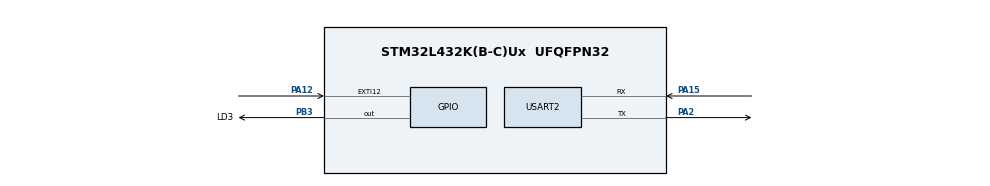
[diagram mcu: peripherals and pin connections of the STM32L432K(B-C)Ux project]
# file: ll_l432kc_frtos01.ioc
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Mcu.Family=STM32L4
Mcu.Name=STM32L432K(B-C)Ux
Mcu.Package=UFQFPN32
NVIC.EXTI15_10_IRQn=true\:5\:0\:true\:false\:true\:true\:true\:true
NVIC.PriorityGroup=NVIC_PRIORITYGROUP_4
NVIC.USART2_IRQn=true\:5\:0\:true\:false\:true\:true\:true\:true
PA12.GPIO_PuPd=GPIO_PULLUP
PA12.Signal=GPXTI12
PA13\ (JTMS-SWDIO).GPIO_Label=SWDIO
PA13\ (JTMS-SWDIO).Mode=Serial_Wire
PA13\ (JTMS-SWDIO).Signal=SYS_JTMS-SWDIO
PA14\ (JTCK-SWCLK).GPIO_Label=SWCLK
PA14\ (JTCK-SWCLK).Mode=Serial_Wire
PA14\ (JTCK-SWCLK).Signal=SYS_JTCK-SWCLK
PA15\ (JTDI).Mode=Asynchronous
PA15\ (JTDI).Signal=USART2_RX
PA2.Mode=Asynchronous
PA2.Signal=USART2_TX
PB3\ (JTDO-TRACESWO).GPIO_Label=LD3
PB3\ (JTDO-TRACESWO).Signal=GPIO_Output
PC14-OSC32_IN\ (PC14).Mode=LSE-External-Oscillator
PC14-OSC32_IN\ (PC14).Signal=RCC_OSC32_IN
PC15-OSC32_OUT\ (PC15).Mode=LSE-External-Oscillator
PC15-OSC32_OUT\ (PC15).Signal=RCC_OSC32_OUT
ProjectManager.HeapSize=0x200
ProjectManager.StackSize=0x400
ProjectManager.TargetToolchain=STM32CubeIDE
RCC.ADCFreq_Value=64000000
RCC.AHBFreq_Value=80000000
RCC.APB1Freq_Value=80000000
RCC.APB1TimFreq_Value=80000000
RCC.APB2Freq_Value=80000000
RCC.APB2TimFreq_Value=80000000
RCC.CortexFreq_Value=80000000
RCC.HCLKFreq_Value=80000000
RCC.HSE_VALUE=8000000
RCC.HSI16_VALUE=16000000
RCC.HSI48_VALUE=48000000
RCC.HSI_VALUE=16000000
RCC.MSI_VALUE=4000000
RCC.PLLMUL=RCC_PLLMUL_4
RCC.PLLN=10
RCC.PLLSourceVirtual=RCC_PLLSOURCE_HSI
RCC.SYSCLKFreq_VALUE=80000000
RCC.SYSCLKSource=RCC_SYSCLKSOURCE_PLLCLK
RCC.USBFreq_Value=64000000
RCC.VCOOutputFreq_Value=160000000
USART2.VirtualMode-Asynchronous=VM_ASYNC
board=NUCLEO-L432KC

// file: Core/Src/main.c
/* USER CODE BEGIN Header */
/**
  ******************************************************************************
  * @file           : main.c
  * @brief          : Main program body
  ******************************************************************************
  * @attention
  *
  * Copyright (c) 2025 STMicroelectronics.
  * All rights reserved.
  *
  * This software is licensed under terms that can be found in the LICENSE file
  * in the root directory of this software component.
  * If no LICENSE file comes with this software, it is provided AS-IS.
  *
  ******************************************************************************
  */
/* USER CODE END Header */
#include "main.h"

void SystemClock_Config(void);
static void MX_GPIO_Init(void);
static void MX_USART2_UART_Init(void);

int main(void)
{

  /* MCU Configuration--------------------------------------------------------*/

  /* Reset of all peripherals, Initializes the Flash interface and the Systick. */
  LL_APB2_GRP1_EnableClock(LL_APB2_GRP1_PERIPH_SYSCFG);
  LL_APB1_GRP1_EnableClock(LL_APB1_GRP1_PERIPH_PWR);

  /* System interrupt init*/
  NVIC_SetPriorityGrouping(NVIC_PRIORITYGROUP_4);

  /* PendSV_IRQn interrupt configuration */
  NVIC_SetPriority(PendSV_IRQn, NVIC_EncodePriority(NVIC_GetPriorityGrouping(),15, 0));
  /* SysTick_IRQn interrupt configuration */
  NVIC_SetPriority(SysTick_IRQn, NVIC_EncodePriority(NVIC_GetPriorityGrouping(),15, 0));

  /* Configure the system clock */
  SystemClock_Config();

  /* Initialize all configured peripherals */
  MX_GPIO_Init();
  MX_USART2_UART_Init();
  /* USER CODE BEGIN 2 */
	/* 初期化関数 */
	setup();
  /* USER CODE END 2 */

  /* Infinite loop */
	while (1) {

    /* USER CODE BEGIN 3 */
		/* 周期処理関数 */
		loop();
	}
  /* USER CODE END 3 */
}

void SystemClock_Config(void)
{
  LL_FLASH_SetLatency(LL_FLASH_LATENCY_4);
  while(LL_FLASH_GetLatency()!= LL_FLASH_LATENCY_4)
  {
  }
  LL_PWR_SetRegulVoltageScaling(LL_PWR_REGU_VOLTAGE_SCALE1);
  while (LL_PWR_IsActiveFlag_VOS() != 0)
  {
  }
  LL_RCC_HSI_Enable();

   /* Wait till HSI is ready */
  while(LL_RCC_HSI_IsReady() != 1)
  {

  }
  LL_RCC_HSI_SetCalibTrimming(16);
  LL_RCC_PLL_ConfigDomain_SYS(LL_RCC_PLLSOURCE_HSI, LL_RCC_PLLM_DIV_1, 10, LL_RCC_PLLR_DIV_2);
  LL_RCC_PLL_EnableDomain_SYS();
  LL_RCC_PLL_Enable();

   /* Wait till PLL is ready */
  while(LL_RCC_PLL_IsReady() != 1)
  {

  }
  LL_RCC_SetSysClkSource(LL_RCC_SYS_CLKSOURCE_PLL);

   /* Wait till System clock is ready */
  while(LL_RCC_GetSysClkSource() != LL_RCC_SYS_CLKSOURCE_STATUS_PLL)
  {

  }
  LL_RCC_SetAHBPrescaler(LL_RCC_SYSCLK_DIV_1);
  LL_RCC_SetAPB1Prescaler(LL_RCC_APB1_DIV_1);
  LL_RCC_SetAPB2Prescaler(LL_RCC_APB2_DIV_1);

  LL_Init1msTick(80000000);

  LL_SetSystemCoreClock(80000000);
}

static void MX_USART2_UART_Init(void)
{

  LL_USART_InitTypeDef USART_InitStruct = {0};

  LL_GPIO_InitTypeDef GPIO_InitStruct = {0};

  LL_RCC_SetUSARTClockSource(LL_RCC_USART2_CLKSOURCE_PCLK1);

  /* Peripheral clock enable */
  LL_APB1_GRP1_EnableClock(LL_APB1_GRP1_PERIPH_USART2);

  LL_AHB2_GRP1_EnableClock(LL_AHB2_GRP1_PERIPH_GPIOA);
  /**USART2 GPIO Configuration
  PA2   ------> USART2_TX
  PA15 (JTDI)   ------> USART2_RX
  */
  GPIO_InitStruct.Pin = LL_GPIO_PIN_2;
  GPIO_InitStruct.Mode = LL_GPIO_MODE_ALTERNATE;
  GPIO_InitStruct.Speed = LL_GPIO_SPEED_FREQ_VERY_HIGH;
  GPIO_InitStruct.OutputType = LL_GPIO_OUTPUT_PUSHPULL;
  GPIO_InitStruct.Pull = LL_GPIO_PULL_NO;
  GPIO_InitStruct.Alternate = LL_GPIO_AF_7;
  LL_GPIO_Init(GPIOA, &GPIO_InitStruct);

  GPIO_InitStruct.Pin = LL_GPIO_PIN_15;
  GPIO_InitStruct.Mode = LL_GPIO_MODE_ALTERNATE;
  GPIO_InitStruct.Speed = LL_GPIO_SPEED_FREQ_VERY_HIGH;
  GPIO_InitStruct.OutputType = LL_GPIO_OUTPUT_PUSHPULL;
  GPIO_InitStruct.Pull = LL_GPIO_PULL_NO;
  GPIO_InitStruct.Alternate = LL_GPIO_AF_3;
  LL_GPIO_Init(GPIOA, &GPIO_InitStruct);

  /* USART2 interrupt Init */
  NVIC_SetPriority(USART2_IRQn, NVIC_EncodePriority(NVIC_GetPriorityGrouping(),5, 0));
  NVIC_EnableIRQ(USART2_IRQn);

  USART_InitStruct.BaudRate = 115200;
  USART_InitStruct.DataWidth = LL_USART_DATAWIDTH_8B;
  USART_InitStruct.StopBits = LL_USART_STOPBITS_1;
  USART_InitStruct.Parity = LL_USART_PARITY_NONE;
  USART_InitStruct.TransferDirection = LL_USART_DIRECTION_TX_RX;
  USART_InitStruct.HardwareFlowControl = LL_USART_HWCONTROL_NONE;
  USART_InitStruct.OverSampling = LL_USART_OVERSAMPLING_16;
  LL_USART_Init(USART2, &USART_InitStruct);
  LL_USART_ConfigAsyncMode(USART2);
  LL_USART_Enable(USART2);

}

static void MX_GPIO_Init(void)
{
  LL_EXTI_InitTypeDef EXTI_InitStruct = {0};
  LL_GPIO_InitTypeDef GPIO_InitStruct = {0};

  /* GPIO Ports Clock Enable */
  LL_AHB2_GRP1_EnableClock(LL_AHB2_GRP1_PERIPH_GPIOC);
  LL_AHB2_GRP1_EnableClock(LL_AHB2_GRP1_PERIPH_GPIOA);
  LL_AHB2_GRP1_EnableClock(LL_AHB2_GRP1_PERIPH_GPIOB);

  /**/
  LL_GPIO_ResetOutputPin(LD3_GPIO_Port, LD3_Pin);

  /**/
  LL_SYSCFG_SetEXTISource(LL_SYSCFG_EXTI_PORTA, LL_SYSCFG_EXTI_LINE12);

  /**/
  EXTI_InitStruct.Line_0_31 = LL_EXTI_LINE_12;
  EXTI_InitStruct.Line_32_63 = LL_EXTI_LINE_NONE;
  EXTI_InitStruct.LineCommand = ENABLE;
  EXTI_InitStruct.Mode = LL_EXTI_MODE_IT;
  EXTI_InitStruct.Trigger = LL_EXTI_TRIGGER_RISING;
  LL_EXTI_Init(&EXTI_InitStruct);

  /**/
  LL_GPIO_SetPinPull(GPIOA, LL_GPIO_PIN_12, LL_GPIO_PULL_UP);

  /**/
  LL_GPIO_SetPinMode(GPIOA, LL_GPIO_PIN_12, LL_GPIO_MODE_INPUT);

  /**/
  GPIO_InitStruct.Pin = LD3_Pin;
  GPIO_InitStruct.Mode = LL_GPIO_MODE_OUTPUT;
  GPIO_InitStruct.Speed = LL_GPIO_SPEED_FREQ_LOW;
  GPIO_InitStruct.OutputType = LL_GPIO_OUTPUT_PUSHPULL;
  GPIO_InitStruct.Pull = LL_GPIO_PULL_NO;
  LL_GPIO_Init(LD3_GPIO_Port, &GPIO_InitStruct);

  /* EXTI interrupt init*/
  NVIC_SetPriority(EXTI15_10_IRQn, NVIC_EncodePriority(NVIC_GetPriorityGrouping(),5, 0));
  NVIC_EnableIRQ(EXTI15_10_IRQn);

}

void Error_Handler(void)
{
  __disable_irq();
  while (1)
  {
  }
}
